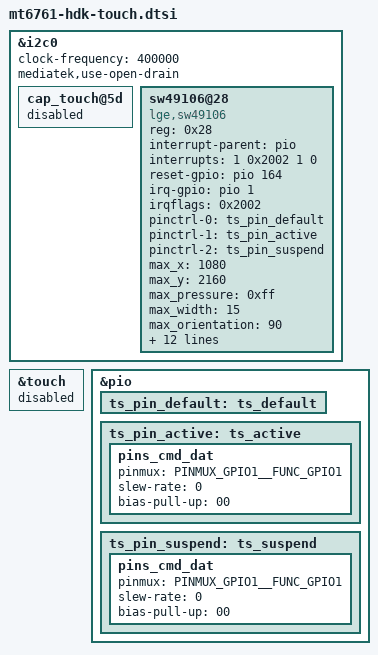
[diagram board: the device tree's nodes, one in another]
/*
 * LG Electronics MT6761 HDK touch device tree source
 *
 * Copyright (c) 2018 LG Electronics Co., Ltd.
 *              http://www.lge.com
 *
 */

&i2c0 {
	#address-cells = <1>;
	#size-cells = <0>;
	clock-frequency = <400000>;
	mediatek,use-open-drain;
	cap_touch@5d {
		status = "disabled";
	};

	sw49106@28 {
		compatible = "lge,sw49106";
		status = "ok";

		reg = <0x28>;

		/* GPIOs */
		interrupt-parent = <&pio>;
		interrupts = <1 0x2002 1 0>;

		/* IRQF_ONESHOT		0x00002000 */
		/* IRQF_TRIGGER_FALLING		0x00000002 */
		/* IRQF_NO_SUSPEND		0x00004000 */

		reset-gpio = <&pio 164 0x0>;
		irq-gpio = <&pio 1 0x2002>;
		irqflags = <0x2002>;

		pinctrl-names = "default", "touch_pin_active", "touch_pin_sleep";	/* Touch GPIO pin name setting */
		pinctrl-0 = <&ts_pin_default>;
		pinctrl-1 = <&ts_pin_active>;		/* Touch GPIO pin active setting */
		pinctrl-2 = <&ts_pin_suspend>;		/* Touch GPIO pin suspend setting */

		/* Caps */
		max_x = <1080>;
		max_y = <2160>;
		max_pressure = <0xff>;
		max_width = <15>;
		max_orientation = <90>;
		max_id = <10>;

		/* role */
		hw_reset_delay = <210>;
		sw_reset_delay = <90>;
		use_lpwg = <1>;
		use_lpwg_test = <1>;
		hide_coordinate = <1>;

		/* firmware */
		use_fw_upgrade = <1>;
		use_firmware = <0>;

		fw_image = "touch/cv5a/lgsic/L0W55CV5_0_28.img";
		panel_spec = "touch/cv5a/lgsic/cv5a_limit.txt";
		panel_spec_mfts_folder = "touch/cv5a/lgsic/cv5a_limit_mfts.txt";
	};
};

/* TOUCH start */
&touch {
	status = "disabled";
};
&pio {
	ts_pin_default: ts_default {
	};

	ts_pin_active: ts_active {
		pins_cmd_dat {
			pinmux = <PINMUX_GPIO1__FUNC_GPIO1>;
			slew-rate = <0>;
			bias-pull-up = <00>;
		};
	};

	ts_pin_suspend: ts_suspend {
		pins_cmd_dat {
			pinmux = <PINMUX_GPIO1__FUNC_GPIO1>;
			slew-rate = <0>;
			bias-pull-up = <00>;
		};
	};
};
/* TOUCH end */
